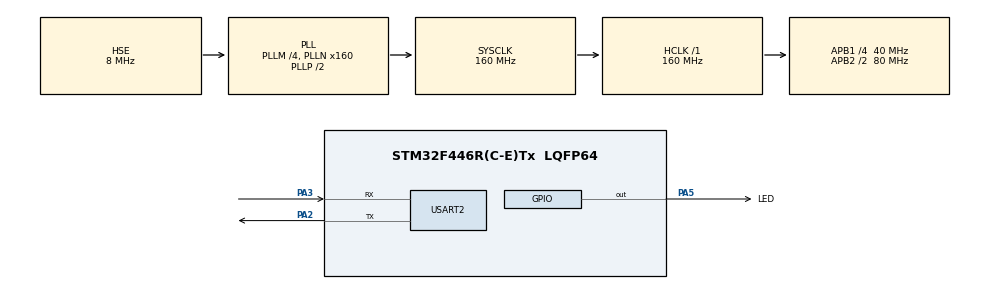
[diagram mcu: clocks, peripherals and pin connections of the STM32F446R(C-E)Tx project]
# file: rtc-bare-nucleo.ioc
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Mcu.Family=STM32F4
Mcu.Name=STM32F446R(C-E)Tx
Mcu.Package=LQFP64
NVIC.PriorityGroup=NVIC_PRIORITYGROUP_4
NVIC.RTC_Alarm_IRQn=true\:0\:0\:false\:false\:true\:true\:true
PA13.Mode=Serial_Wire
PA13.Signal=SYS_JTMS-SWDIO
PA14.Mode=Serial_Wire
PA14.Signal=SYS_JTCK-SWCLK
PA2.Mode=Asynchronous
PA2.Signal=USART2_TX
PA3.Mode=Asynchronous
PA3.Signal=USART2_RX
PA5.GPIO_Label=LED
PA5.Signal=GPIO_Output
PC14-OSC32_IN.Mode=LSE-External-Oscillator
PC14-OSC32_IN.Signal=RCC_OSC32_IN
PC15-OSC32_OUT.Mode=LSE-External-Oscillator
PC15-OSC32_OUT.Signal=RCC_OSC32_OUT
PH0-OSC_IN.Mode=HSE-External-Oscillator
PH0-OSC_IN.Signal=RCC_OSC_IN
PH1-OSC_OUT.Mode=HSE-External-Oscillator
PH1-OSC_OUT.Signal=RCC_OSC_OUT
ProjectManager.HeapSize=0x200
ProjectManager.StackSize=0x400
ProjectManager.TargetToolchain=STM32CubeIDE
RCC.AHBFreq_Value=160000000
RCC.APB1CLKDivider=RCC_HCLK_DIV4
RCC.APB1Freq_Value=40000000
RCC.APB1TimFreq_Value=80000000
RCC.APB2CLKDivider=RCC_HCLK_DIV2
RCC.APB2Freq_Value=80000000
RCC.APB2TimFreq_Value=160000000
RCC.CortexFreq_Value=160000000
RCC.HCLKFreq_Value=160000000
RCC.HSE_VALUE=8000000
RCC.PLLM=4
RCC.PLLN=160
RCC.PLLQ=7
RCC.PLLSourceVirtual=RCC_PLLSOURCE_HSE
RCC.RCC_RTC_Clock_SourceVirtual=RCC_RTCCLKSOURCE_LSE
RCC.SYSCLKFreq_VALUE=160000000
RCC.SYSCLKSource=RCC_SYSCLKSOURCE_PLLCLK
RCC.USBFreq_Value=45714285.71428572
RCC.VCOOutputFreq_Value=320000000
RTC.Alarm=RTC_ALARM_A
RTC.Hours=12
RTC.Hours_A=12
RTC.Minutes=30
RTC.Minutes_A=30
RTC.Seconds=15
RTC.Seconds_A=20
USART2.VirtualMode=VM_ASYNC
VP_RTC_VS_RTC_Activate.Mode=RTC_Enabled
VP_RTC_VS_RTC_Alarm_A_Intern.Mode=Alarm A
VP_RTC_VS_RTC_Calendar.Mode=RTC_Calendar
board=custom

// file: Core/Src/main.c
/* USER CODE BEGIN Header */
/**
  ******************************************************************************
  * @file           : main.c
  * @brief          : Main program body
  ******************************************************************************
  * @attention
  *
  * <h2><center>&copy; Copyright (c) 2020 STMicroelectronics.
  * All rights reserved.</center></h2>
  *
  * This software component is licensed by ST under BSD 3-Clause license,
  * the "License"; You may not use this file except in compliance with the
  * License. You may obtain a copy of the License at:
  *                        opensource.org/licenses/BSD-3-Clause
  *
  ******************************************************************************
  */
/* USER CODE END Header */

#include "main.h"

/* USER CODE BEGIN Includes */
#include "stdio.h"
#include "stdlib.h"
/* USER CODE END Includes */

RTC_HandleTypeDef hrtc;

UART_HandleTypeDef huart2;

/* USER CODE BEGIN PV */
volatile uint8_t alarmFlag = 0;
/* USER CODE END PV */

void SystemClock_Config(void);
static void MX_GPIO_Init(void);
static void MX_RTC_Init(void);
static void MX_USART2_UART_Init(void);
/* USER CODE BEGIN PFP */
void HAL_RTC_AlarmAEventCallback(RTC_HandleTypeDef * hrtc);
/* USER CODE END PFP */

/* USER CODE BEGIN 0 */
/*
 * Alarm event handler. Interrupt happens when actual time is equals to alarm
 */
void HAL_RTC_AlarmAEventCallback (RTC_HandleTypeDef * hrtc)
{
	alarmFlag = 1;
	return;
}
/* USER CODE END 0 */

int main(void)
{

  /* MCU Configuration--------------------------------------------------------*/

  /* Reset of all peripherals, Initializes the Flash interface and the Systick. */
  HAL_Init();

  /* Configure the system clock */
  SystemClock_Config();

  /* Initialize all configured peripherals */
  MX_GPIO_Init();
  MX_RTC_Init();
  MX_USART2_UART_Init();

  /* Infinite loop */
  /* USER CODE BEGIN WHILE */
  RTC_TimeTypeDef gTime;	//Time struct variable
  RTC_DateTypeDef gDate;
  uint8_t time[11];			//Array to store time as string. Format: hh:mm:ss
  while (1)
  {
	  //Function call to get time. Returns hours, minutes and seconds on gTime struct variable.
	  HAL_RTC_GetTime(&hrtc, &gTime, RTC_FORMAT_BIN);
	  HAL_RTC_GetDate(&hrtc, &gDate, RTC_FORMAT_BIN);

	  //Function call to store as string second argument into first argument. Returns number of bytes of string copied.
	  uint8_t sizeBuffer = sprintf((char *)time, "%02u:%02u:%02u\n", gTime.Hours, gTime.Minutes, gTime.Seconds);

	  //Function call to transmit time array through serial port
  	  HAL_UART_Transmit(&huart2, time, sizeBuffer, 500);

  	  if(alarmFlag)
  	  {
  		  alarmFlag = 0;
  		  uint8_t alarmArray[] = "Alarm!\n";
  		  HAL_UART_Transmit(&huart2, alarmArray, sizeof(alarmArray), 200);
  	  }

  	  //Wait for 1 second (1000 ms)
  	  HAL_Delay(1000);
    /* USER CODE END WHILE */

  }
}

void SystemClock_Config(void)
{
  RCC_OscInitTypeDef RCC_OscInitStruct = {0};
  RCC_ClkInitTypeDef RCC_ClkInitStruct = {0};
  RCC_PeriphCLKInitTypeDef PeriphClkInitStruct = {0};

  /** Configure the main internal regulator output voltage
  */
  __HAL_RCC_PWR_CLK_ENABLE();
  __HAL_PWR_VOLTAGESCALING_CONFIG(PWR_REGULATOR_VOLTAGE_SCALE1);
  /** Initializes the CPU, AHB and APB busses clocks
  */
  RCC_OscInitStruct.OscillatorType = RCC_OSCILLATORTYPE_HSE|RCC_OSCILLATORTYPE_LSE;
  RCC_OscInitStruct.HSEState = RCC_HSE_ON;
  RCC_OscInitStruct.LSEState = RCC_LSE_ON;
  RCC_OscInitStruct.PLL.PLLState = RCC_PLL_ON;
  RCC_OscInitStruct.PLL.PLLSource = RCC_PLLSOURCE_HSE;
  RCC_OscInitStruct.PLL.PLLM = 4;
  RCC_OscInitStruct.PLL.PLLN = 160;
  RCC_OscInitStruct.PLL.PLLP = RCC_PLLP_DIV2;
  RCC_OscInitStruct.PLL.PLLQ = 7;
  RCC_OscInitStruct.PLL.PLLR = 2;
  if (HAL_RCC_OscConfig(&RCC_OscInitStruct) != HAL_OK)
  {
    Error_Handler();
  }
  /** Initializes the CPU, AHB and APB busses clocks
  */
  RCC_ClkInitStruct.ClockType = RCC_CLOCKTYPE_HCLK|RCC_CLOCKTYPE_SYSCLK
                              |RCC_CLOCKTYPE_PCLK1|RCC_CLOCKTYPE_PCLK2;
  RCC_ClkInitStruct.SYSCLKSource = RCC_SYSCLKSOURCE_PLLCLK;
  RCC_ClkInitStruct.AHBCLKDivider = RCC_SYSCLK_DIV1;
  RCC_ClkInitStruct.APB1CLKDivider = RCC_HCLK_DIV4;
  RCC_ClkInitStruct.APB2CLKDivider = RCC_HCLK_DIV2;

  if (HAL_RCC_ClockConfig(&RCC_ClkInitStruct, FLASH_LATENCY_5) != HAL_OK)
  {
    Error_Handler();
  }
  PeriphClkInitStruct.PeriphClockSelection = RCC_PERIPHCLK_RTC;
  PeriphClkInitStruct.RTCClockSelection = RCC_RTCCLKSOURCE_LSE;
  if (HAL_RCCEx_PeriphCLKConfig(&PeriphClkInitStruct) != HAL_OK)
  {
    Error_Handler();
  }
}

static void MX_RTC_Init(void)
{

  RTC_TimeTypeDef sTime = {0};
  RTC_DateTypeDef sDate = {0};
  RTC_AlarmTypeDef sAlarm = {0};

  /** Initialize RTC Only
  */
  hrtc.Instance = RTC;
  hrtc.Init.HourFormat = RTC_HOURFORMAT_24;
  hrtc.Init.AsynchPrediv = 127;
  hrtc.Init.SynchPrediv = 255;
  hrtc.Init.OutPut = RTC_OUTPUT_DISABLE;
  hrtc.Init.OutPutPolarity = RTC_OUTPUT_POLARITY_HIGH;
  hrtc.Init.OutPutType = RTC_OUTPUT_TYPE_OPENDRAIN;
  if (HAL_RTC_Init(&hrtc) != HAL_OK)
  {
    Error_Handler();
  }

  /** Initialize RTC and set the Time and Date
  */
  sTime.Hours = 0x12;
  sTime.Minutes = 0x30;
  sTime.Seconds = 0x15;
  sTime.DayLightSaving = RTC_DAYLIGHTSAVING_NONE;
  sTime.StoreOperation = RTC_STOREOPERATION_RESET;
  if (HAL_RTC_SetTime(&hrtc, &sTime, RTC_FORMAT_BCD) != HAL_OK)
  {
    Error_Handler();
  }
  sDate.WeekDay = RTC_WEEKDAY_MONDAY;
  sDate.Month = RTC_MONTH_JANUARY;
  sDate.Date = 0x1;
  sDate.Year = 0x0;

  if (HAL_RTC_SetDate(&hrtc, &sDate, RTC_FORMAT_BCD) != HAL_OK)
  {
    Error_Handler();
  }
  /** Enable the Alarm A
  */
  sAlarm.AlarmTime.Hours = 0x12;
  sAlarm.AlarmTime.Minutes = 0x30;
  sAlarm.AlarmTime.Seconds = 0x20;
  sAlarm.AlarmTime.SubSeconds = 0x0;
  sAlarm.AlarmTime.DayLightSaving = RTC_DAYLIGHTSAVING_NONE;
  sAlarm.AlarmTime.StoreOperation = RTC_STOREOPERATION_RESET;
  sAlarm.AlarmMask = RTC_ALARMMASK_NONE;
  sAlarm.AlarmSubSecondMask = RTC_ALARMSUBSECONDMASK_ALL;
  sAlarm.AlarmDateWeekDaySel = RTC_ALARMDATEWEEKDAYSEL_DATE;
  sAlarm.AlarmDateWeekDay = 0x1;
  sAlarm.Alarm = RTC_ALARM_A;
  if (HAL_RTC_SetAlarm_IT(&hrtc, &sAlarm, RTC_FORMAT_BCD) != HAL_OK)
  {
    Error_Handler();
  }

}

static void MX_USART2_UART_Init(void)
{

  huart2.Instance = USART2;
  huart2.Init.BaudRate = 115200;
  huart2.Init.WordLength = UART_WORDLENGTH_8B;
  huart2.Init.StopBits = UART_STOPBITS_1;
  huart2.Init.Parity = UART_PARITY_NONE;
  huart2.Init.Mode = UART_MODE_TX_RX;
  huart2.Init.HwFlowCtl = UART_HWCONTROL_NONE;
  huart2.Init.OverSampling = UART_OVERSAMPLING_16;
  if (HAL_UART_Init(&huart2) != HAL_OK)
  {
    Error_Handler();
  }

}

static void MX_GPIO_Init(void)
{
  GPIO_InitTypeDef GPIO_InitStruct = {0};

  /* GPIO Ports Clock Enable */
  __HAL_RCC_GPIOC_CLK_ENABLE();
  __HAL_RCC_GPIOH_CLK_ENABLE();
  __HAL_RCC_GPIOA_CLK_ENABLE();

  /*Configure GPIO pin Output Level */
  HAL_GPIO_WritePin(LED_GPIO_Port, LED_Pin, GPIO_PIN_RESET);

  /*Configure GPIO pin : LED_Pin */
  GPIO_InitStruct.Pin = LED_Pin;
  GPIO_InitStruct.Mode = GPIO_MODE_OUTPUT_PP;
  GPIO_InitStruct.Pull = GPIO_NOPULL;
  GPIO_InitStruct.Speed = GPIO_SPEED_FREQ_LOW;
  HAL_GPIO_Init(LED_GPIO_Port, &GPIO_InitStruct);

}

void Error_Handler(void)
{
}

/************************ (C) COPYRIGHT STMicroelectronics *****END OF FILE****/
